# AC78xx register map
Vendor: AutoChips; Series: AC78xx; File version: 1.0
CPU: CM3 r2p1, little endian, MPU, no FPU, 3 interrupt priority bits
Registers are 32-bit, read-write, no defined reset value unless marked. A register's access mark holds for its fields unless they carry their own. Offsets are from the block's base; [hi:lo] are bit positions; {n}, {i} and the like mark numbered series.

## GPIOA — General Purpose Input/Output
Base 0x20080000
Same registers: GPIOB 0x20080030, GPIOC 0x20080060, GPIOD 0x20080090, GPIOE 0x200800C0
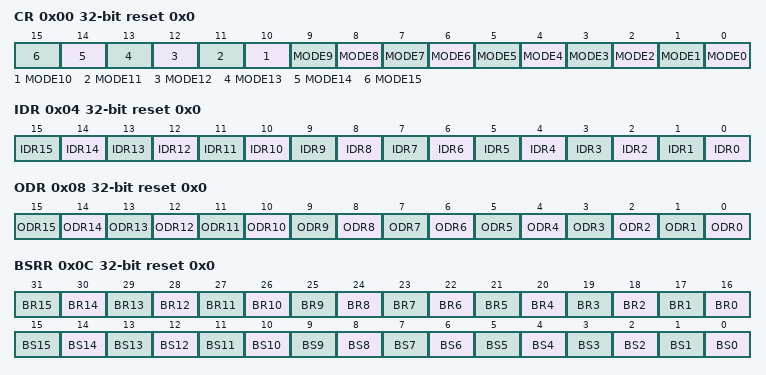
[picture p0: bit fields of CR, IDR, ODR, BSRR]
0x00 CR reset 0x0 — GPIOx Configuration Register
  [n] MODE{n} (n=0..15) — MODE{n}[0] bits (Port x mode bits, pin {n})
0x04 IDR ro reset 0x0 — GPIO Input Data Register
  [n] IDR{n} rw (n=0..15) — Port input data, bit {n}
0x08 ODR reset 0x0 — GPIO Output Data Register
  [n] ODR{n} (n=0..15) — Port output data, bit {n}
0x0C BSRR reset 0x0 — GPIO Bit Set, Reset Register
  [n+16] BR{n} (n=0..15) — Port x, Reset bit {n}
  [n] BS{n} (n=0..15) — Port x, Set bit {n}
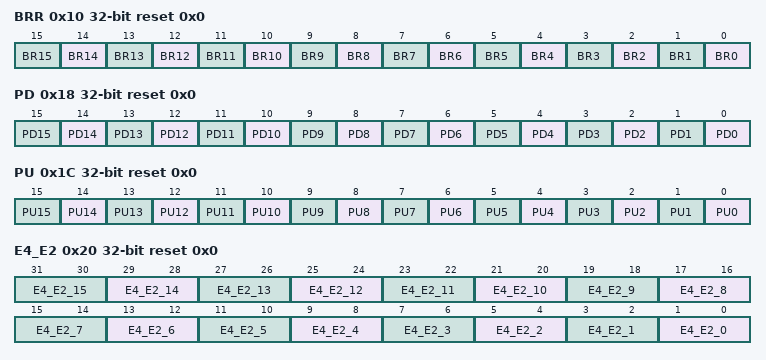
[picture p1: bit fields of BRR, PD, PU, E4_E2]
0x10 BRR reset 0x0 — GPIO Bit Reset Register
  [n] BR{n} (n=0..15) — Port x, Reset bit {n}
0x18 PD reset 0x0 — GPIO Pull Down Register
  [n] PD{n} (n=0..15) — Port x, Pin {n} pull down
0x1C PU reset 0x0 — GPIO Pull Up Register
  [n] PU{n} (n=0..15) — Port x, Pin {n} pull up
0x20 E4_E2 reset 0x0 — GPIO E4_E2 Register
  [all] fields
    0=4mA (Driving 4mA); 1=8mA (Driving 8mA); 2=12mA (Driving 12mA); 3=16mA (Driving 16mA)
  [2n+1:2n] E4_E2_{n} (n=0..15) — Port x, Pin {n} driving current

## PMUX — PinMux Function
Base 0x20080140
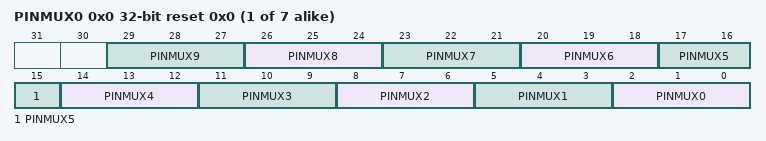
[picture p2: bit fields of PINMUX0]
{0x0+4i} PINMUX{i} (i=0..6) reset 0x0 — PinMux Function Register
  [all] fields
    {v}=FUNC{v} (Function {v}) (v=0..3)
  [3n+2:3n] PINMUX{n} (n=0..9) — GPIO_PA{n} pinmux

## EXTI — External Interrupt
Base 0x20080160
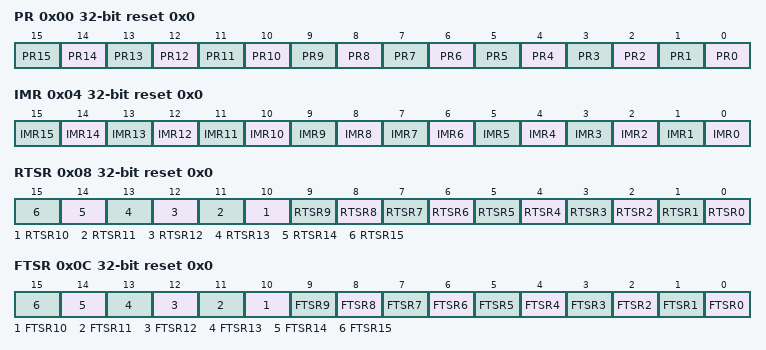
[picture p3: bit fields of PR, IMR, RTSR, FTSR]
0x00 PR reset 0x0 — EXTI Pending Register
  [n] PR{n} (n=0..15) — GPIOx_PIN{n} exti flag
0x04 IMR reset 0x0 — EXTI Mask Register
  [n] IMR{n} (n=0..15) — GPIOx_PIN{n} exti mask flag
0x08 RTSR reset 0x0 — EXTI Rasing edge Register
  [n] RTSR{n} (n=0..15) — GPIOx_PIN{n} exti rasing edge enable flag
0x0C FTSR reset 0x0 — EXTI Falling edge Register
  [n] FTSR{n} (n=0..15) — GPIOx_PIN{n} exti falling edge enable flag
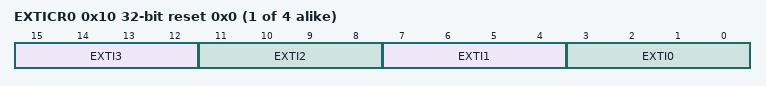
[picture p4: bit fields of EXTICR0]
{0x10+4i} EXTICR{i} (i=0..3) reset 0x0 — EXTI Control Register
  [all] fields
    0=PA (PA[x] Pin); 1=PB (PB[x] Pin); 2=PC (PC[x] Pin); 3=PD (PD[x] Pin); 4=PE (PE[x] Pin)
  [15:12] EXTI3 — select PORTx for GPIOx_PIN4 external interrupt
  [11:8] EXTI2 — select PORTx for GPIOx_PIN2 external interrupt
  [7:4] EXTI1 — select PORTx for GPIOx_PIN1 external interrupt
  [3:0] EXTI0 — select PORTx for GPIOx_PIN0 external interrupt

## CAN1
Base 0x400078A0; register names take the prefix CAN1_
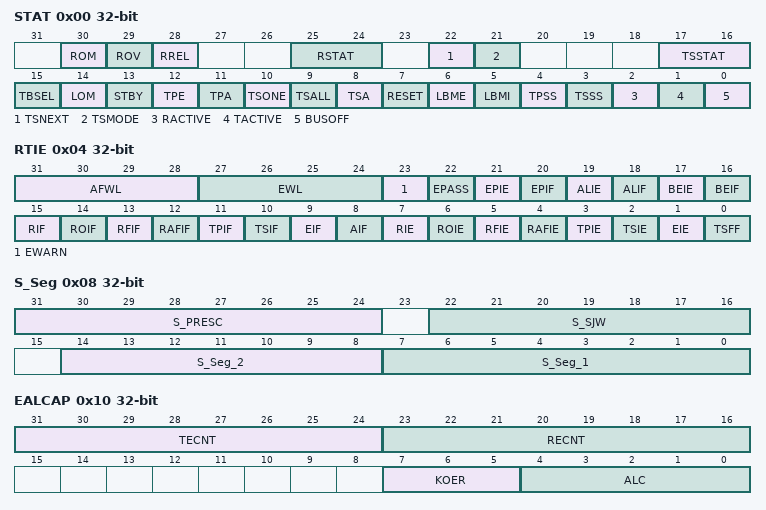
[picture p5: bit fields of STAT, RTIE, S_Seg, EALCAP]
0x00 STAT — configuration and status register
  [30] ROM — Receive Buffer Overflow Mode
  [29] ROV — Receive Buffer Overflow
  [28] RREL — Receive Buffer Release
  [25:24] RSTAT ro — Receive Buffer status bits
  [22] TSNEXT — Transmit Buffer Secondary next
  [21] TSMODE — Transmit buffer Secondary operation Mode
  [17:16] TSSTAT — Transmit Secondary status bits
  [15] TBSEL — Transmit Buffer Select
  [14] LOM — Listen Only mode
  [13] STBY — Transceiver Standby mode
  [12] TPE — Transmit Primary Enable
  [11] TPA — Transmit Primary Abort
  [10] TSONE — Transmit Secondary one Frame
  [9] TSALL — Transmit Secondary All frames
  [8] TSA — Transmit Secondary Abort
  [7] RESET — reset request bit
  [6] LBME — Loop back mode, external
  [5] LBMI — Loop back mode internal
  [4] TPSS — Transmission Primary single shot mode for PTB
  [3] TSSS — Transmission Secondary single shot mode for STB
  [2] RACTIVE — Reception Active
  [1] TACTIVE — Transmission Active
  [0] BUSOFF — BUS off status
0x04 RTIE — Receive and Transmit Interrupt Enable Register
  [31:28] AFWL — Receive Buffer Almost Full Warning Limit
  [27:24] EWL — Programmable Error Warnig Limit
  [23] EWARN — Error Warning Limit Reached
  [22] EPASS — Error Passive Mode Active enable bit
  [21] EPIE — Error Passive Interrupt Enable
  [20] EPIF — Error Passive Interrupt Flag
  [19] ALIE — Arbitration Lost Interrupt Enable
  [18] ALIF — Arbitration Lost Interrupt Flag
  [17] BEIE — Bus Error Interrupt Enable
  [16] BEIF — Bus Error Interrupt flag
  [15] RIF — Receive Interrupt flag
  [14] ROIF — RB Overflow Interrupt flag
  [13] RFIF — RB Full Interrupt flag
  [12] RAFIF — RB Almost Full Interrupt flag
  [11] TPIF — Transmission Primary Interrupt Flag
  [10] TSIF — Transmission Secondary Interrupt Flag
  [9] EIF — Error Interrupt Flag
  [8] AIF — Abort Interrupt Flag
  [7] RIE — Receive Interrupt enable
  [6] ROIE — RB Overflow Interrupt enable
  [5] RFIE — RB Full Interrupt Enable
  [4] RAFIE — RB Almost Full Interrupt Enable
  [3] TPIE — Transmit Primary Interrupt Enable
  [2] TSIE — Transmit Secondary Interrupt Enable
  [1] EIE — Error Interrupt Enable
  [0] TSFF — Transmit Secondary Buffer full flag
0x08 S_Seg — Bit Timing Register
  [31:24] S_PRESC — Prescaler
  [22:16] S_SJW — Synchronization Jump Width
  [14:8] S_Seg_2 — Bit Timing Segment 2
  [7:0] S_Seg_1 — Bit Timing Segment 1
0x10 EALCAP — Error and Arbitration Lost Capture Register
  [31:24] TECNT ro — Transmit Error Count
  [23:16] RECNT ro — Receive Error Count
  [7:5] KOER ro — Kind of Error
  [4:0] ALC ro — Arbitration Lost Capture
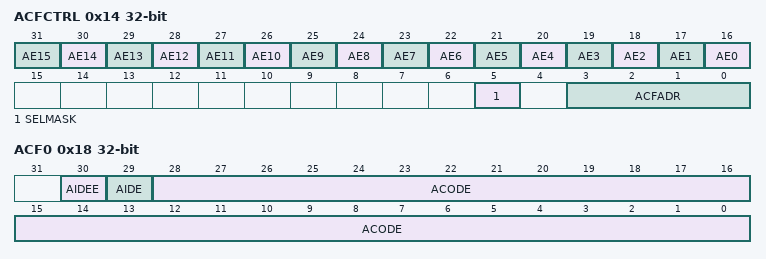
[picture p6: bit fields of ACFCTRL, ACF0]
0x14 ACFCTRL — Acceptance Filter Control Register
  [n+16] AE{n} (n=0..15) — Acceptance Filter Enable
  [5] SELMASK — Select Acceptance MASK
  [3:0] ACFADR — Acceptance filter address
0x18 ACF0 — Acceptance Code Register
  [30] AIDEE — Acceptance Mask IDE bit check enable
  [29] AIDE — Acceptance Mask IDE Bit value
  [28:0] ACODE — Acceptance Code
0x1C VER — Version Information Register 0
  [15:0] VER — Version of CAN-CTRL

## CAN2
Base 0x40007CA0; register names take the prefix CAN2_
Registers as CAN1.

## LIN0 — LIN Interface
Base 0x40007000; register names take the prefix LIN0_
0x00 SYS — LIN System Control Register
  [1:0] LM — LIN Mode Select
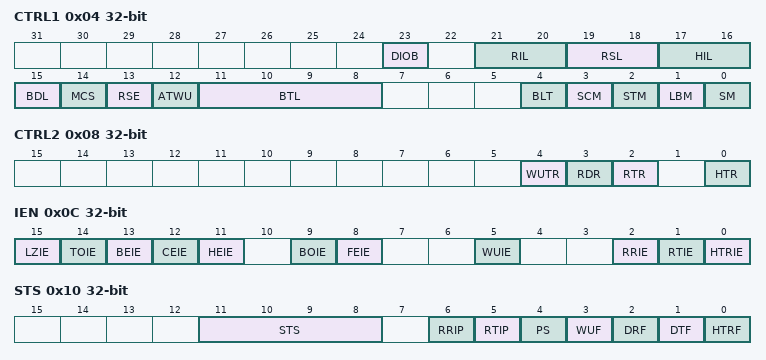
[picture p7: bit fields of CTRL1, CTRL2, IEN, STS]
0x04 CTRL1 — LIN Control Register 1
  [23] DIOB — LIN State machine goes to IDLE on bit error detection
  [21:20] RIL — Response inter byte length between response data
  [19:18] RSL — Response inter space length, only for master mode
  [17:16] HIL — Header inter-byte length between sync field and PID filed in master mode
  [15] BDL — Break delimiter length
  [14] MCS — Disable the hardware checksum calculation
  [13] RSE — LIN Slave Automatic Resynchronization Enable
  [12] ATWU — Control the behavior of the LIN hardware during sleep mode
  [11:8] BTL — LIN Break field transmit length in master mode
  [4] BLT — LIN Break Length threshold select
  [3] SCM — LIN software control Mode enable bit
  [2] STM — LIN Self Test Mode enable bit
  [1] LBM — LIN Loop back Mode enable bit
  [0] SM — LIN Slave Mode enable bit
0x08 CTRL2 — LIN Control register 2
  [4] WUTR — Wakeup TX Request
  [3] RDR — Response Discard Request
  [2] RTR — Data Transmission Request
  [0] HTR — Header Transmission Requeset
0x0C IEN — LIN Interrupt Enable Register
  [15] LZIE — Long Zero Interrupt Enable
  [14] TOIE — Timeout Interrupt Enable
  [13] BEIE — Bit Error Interrupt Enable
  [12] CEIE — Checksum error Interrupt enable
  [11] HEIE — Header Error Interrupt Enable
  [9] BOIE — Buffer Overrun Interrupt enable
  [8] FEIE — Framing Error Interrupt Enable
  [5] WUIE — Wakeup Interrupt enable
  [2] RRIE — Response Reception Complete Interrupt Enable
  [1] RTIE — Response Transmitted Interrupt Enable
  [0] HTRIE — Header Received Interrupt enable
0x10 STS — LIN Status Register
  [11:8] STS ro — LIN mode status
  [6] RRIP ro — Response RX in Progress
  [5] RTIP ro — Response TX in Progress
  [4] PS ro — LIN receive pin state
  [3] WUF write-clear — Wake-up Flag
  [2] DRF write-clear — Data Reception Completed Flag
  [1] DTF write-clear — Data Transmission Completed Flag
  [0] HTRF write-clear — Header Transmission/Reception Flag
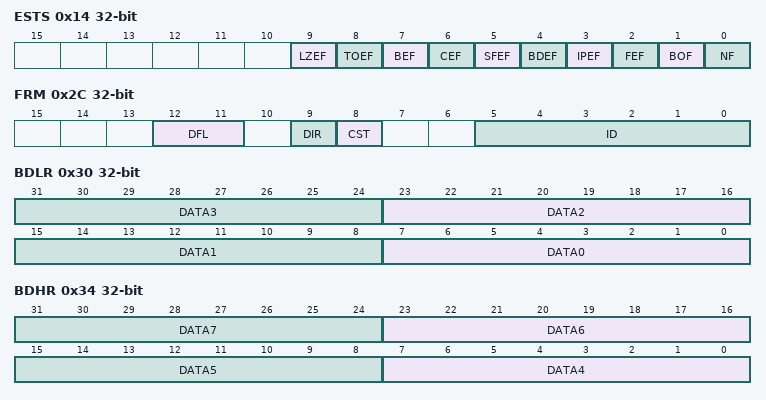
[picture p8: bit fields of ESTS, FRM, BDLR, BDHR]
0x14 ESTS write-clear — LIN Error Status register
  [9] LZEF — Long Zero Error Flag
  [8] TOEF — Time Out Error Flag
  [7] BEF — Bit Error Flag
  [6] CEF — Checksum Error Flag
  [5] SFEF — Synch Field Error Flag
  [4] BDEF — Break Delimiter Error Flag
  [3] IPEF — Identifier Parity Error Flag
  [2] FEF — Framing Error Flag
  [1] BOF — Buffer Overrun Flag
  [0] NF — Noise Flag
0x18 TO1 — LIN Time out control register 1
  [5:0] HTO — Header timeout value
0x1C TO2 — LIN Time out control register 2
  [0] TOEN — Header timeout enable
0x20 IBR — LIN integer baud rate register
  [11:0] IBR — Integer baud rate divide value
0x24 FBR — LIN fractional baud rate register
  [3:0] FBR — Fractional baud rate divide value
0x28 CS — LIN Checksum field register
  [7:0] CS — LIN Checksum field value
0x2C FRM — LIN Frame Control register
  [12:11] DFL — Data field length
  [9] DIR — Direction
  [8] CST — Checksum type
  [5:0] ID — Identifier
0x30 BDLR — Buffer data low register
  [8n+7:8n] DATA{n} (n=0..3)
0x34 BDHR — Buffer data High register
  [8n-25:8n-32] DATA{n} (n=4..7)
0x38 IFEN — LIN ID Filter enable register
  [15:0] EN — Filter Number Enable
0x3C IFMR — LIN ID Filter mode register
  [7:0] IFM — ID Filter Mode
0x40 IFMI — LIN ID Filter match index register
  [4:0] IFMI — ID Filter match index
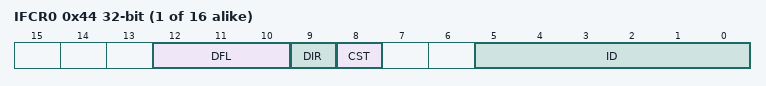
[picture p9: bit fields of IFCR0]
{0x44+4i} IFCR{i} (i=0..15) — LIN ID filter control register
  [12:10] DFL — Data Field Length
  [9] DIR — Direction
  [8] CST — Checksum type
  [5:0] ID — Identifier
